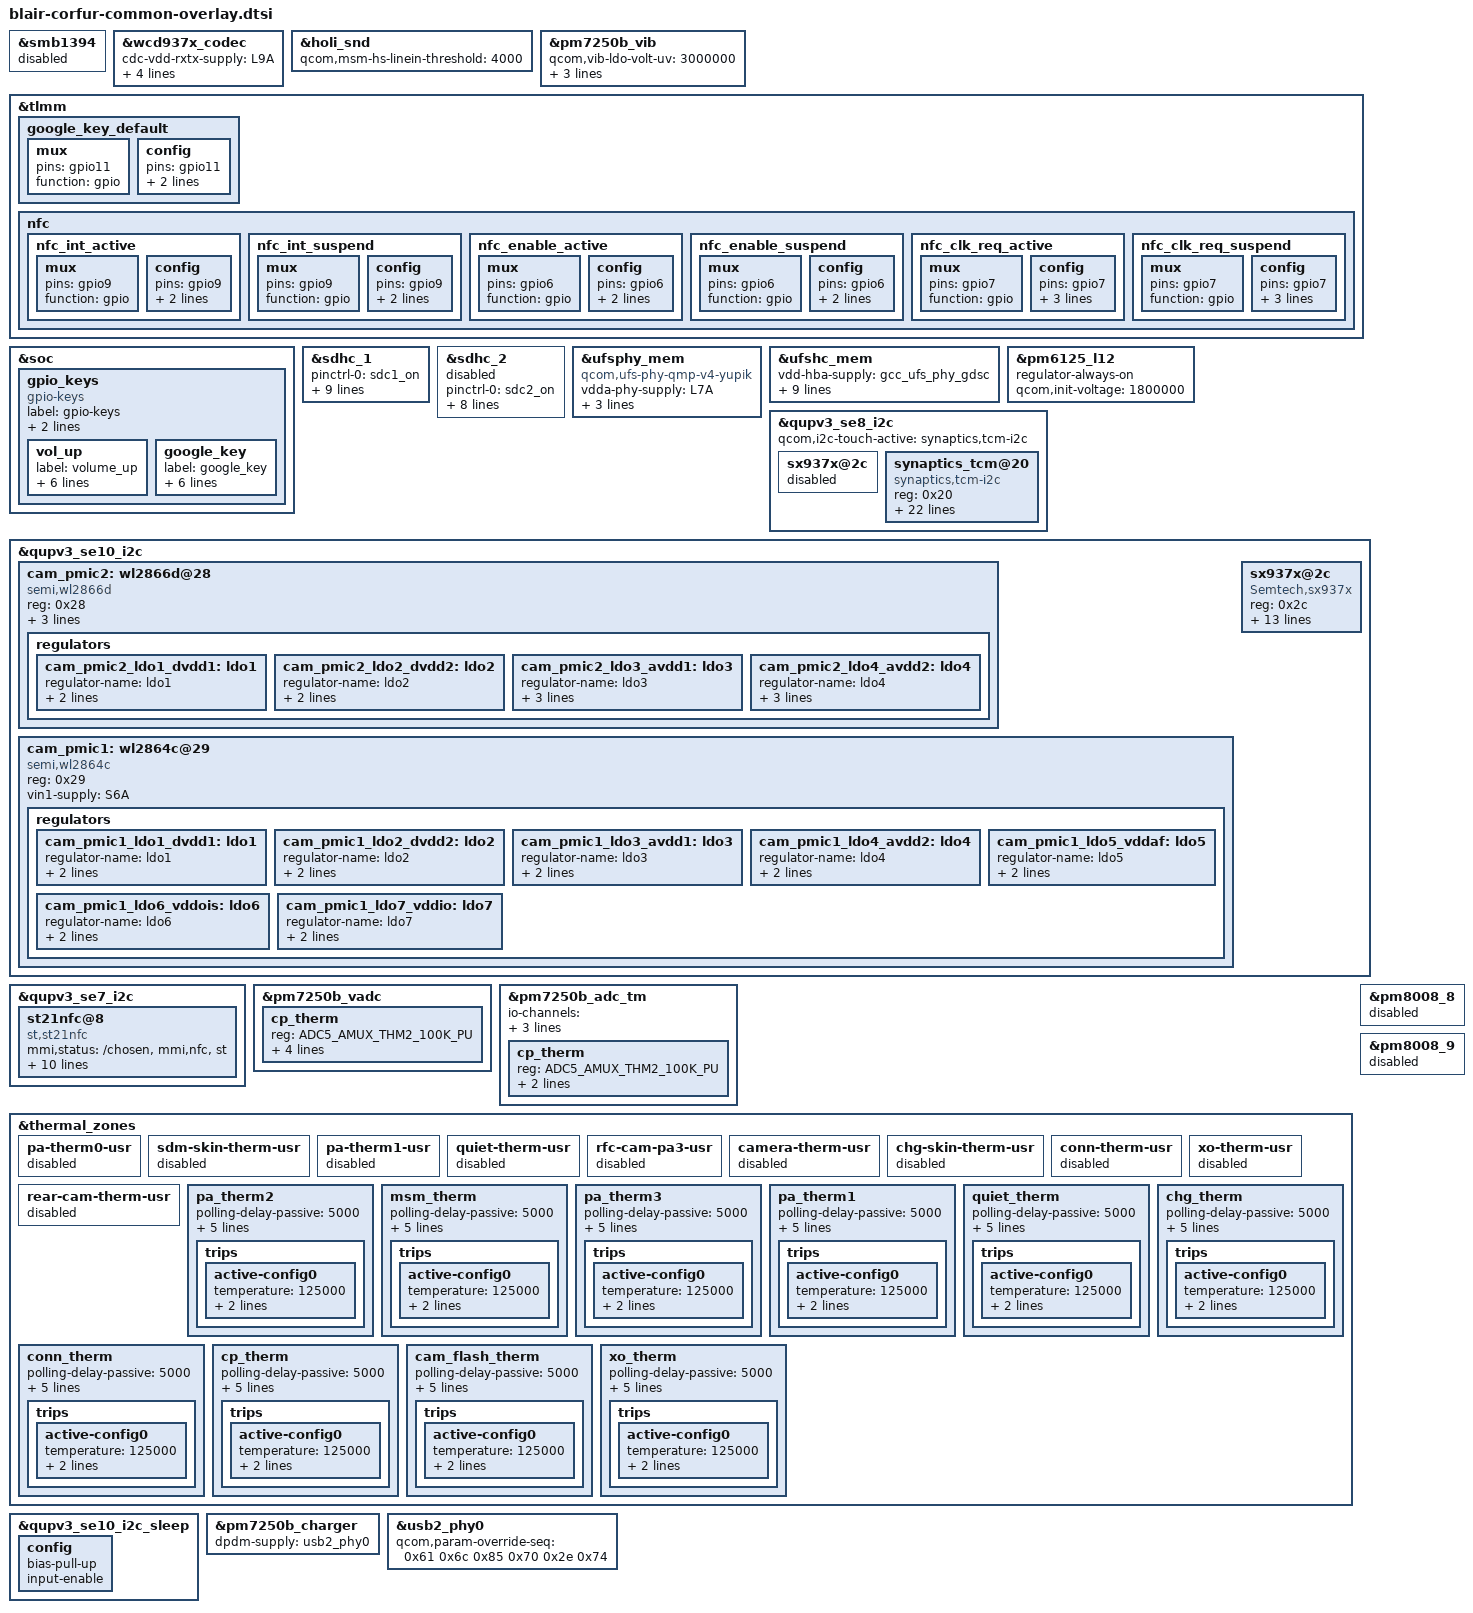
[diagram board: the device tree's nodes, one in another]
/* Copyright (c) 2021, The Linux Foundation. All rights reserved.
 *
 * This program is free software; you can redistribute it and/or modify
 * it under the terms of the GNU General Public License version 2 and
 * only version 2 as published by the Free Software Foundation.
 *
 * This program is distributed in the hope that it will be useful,
 * but WITHOUT ANY WARRANTY; without even the implied warranty of
 * MERCHANTABILITY or FITNESS FOR A PARTICULAR PURPOSE.  See the
 * GNU General Public License for more details.
 */

#include "blair-pm6125-moto-common-overlay.dtsi"
#include <dt-bindings/gpio/gpio.h>
#include <dt-bindings/input/linux-event-codes.h>
#include "holi-pmic-overlay-pm6125.dtsi"
#include "holi-thermal-overlay-pm6125.dtsi"
#include "display/holi-sde-display-mtp-pm6125.dtsi"
#include <dt-bindings/iio/qti_power_supply_iio.h>
#include "corfur-fps-overlay.dtsi"
#include "corfur-display.dtsi"
#include "corfuq-touchscreen.dtsi"
#include "holi-audio-wcd9370-aw882xx-acf-overlay.dtsi"
#include "moto_therm_sys_temp.dtsi"
#include "corfup-charger.dtsi"
#include "camera/blair-camera-sensor-mot-corfup-overlay.dtsi"
#include "camera/holi-camera-sensor-mot-corfup-dvt1-overlay.dtsi"
#include "blair-corfur-fmr-overlay.dtsi"

&smb1394 {
	status = "disabled";
};

&wcd937x_codec {
	cdc-vdd-rxtx-supply = <&L9A>;
	cdc-vddpx-supply = <&L9A>;
	qcom,cdc-static-supplies = "cdc-vdd-rxtx",
				   "cdc-vddpx";
	/*
	 * Overriding cdc-vdd-mic-bias-supply to dummy value
	 * to avoid compilation errors as BOB is not definied
	 * for pm6125
	 */
	cdc-vdd-mic-bias-supply = <>;
};

&holi_snd {
	qcom,msm-hs-linein-threshold = <4000>;
};

&pm7250b_vib {
	qcom,vib-ldo-volt-uv = <3000000>;
	qcom,vib-dis-short-long;
	qcom,vib-dis-short-long-val = <70>;
	qcom,vib-ldo-volt-uv-long = <2500000>;
};

&tlmm {
	google_key_default: google_key_default {
		mux {
			pins = "gpio11";
			function = "gpio";
		};

		config {
			pins = "gpio11";
			drive-strength = <2>;
			bias-pull-up;
		};
	};

	nfc {
		nfc_int_active: nfc_int_active {
			/* active state */
			mux {
				/* GPIO 9: NFC Read Interrupt */
				pins = "gpio9";
				function = "gpio";
			};

			config {
				pins = "gpio9";
				drive-strength = <2>; /* 2 MA */
				bias-disable;
			};
		};

		nfc_int_suspend: nfc_int_suspend {
			/* sleep state */
			mux {
				/* GPIO 9: NFC Read Interrupt */
				pins = "gpio9";
				function = "gpio";
			};

			config {
				pins = "gpio9";
				drive-strength = <2>; /* 2 MA */
				bias-disable;
			};
		};

		nfc_enable_active: nfc_enable_active {
			mux {
				/* 6: Enable */
				pins = "gpio6";
				function = "gpio";
			};

			config {
				pins = "gpio6";
				drive-strength = <2>; /* 2 MA */
				bias-disable;
			};
		};

		nfc_enable_suspend: nfc_enable_suspend {
			mux {
				/* 6: Enable */
				pins = "gpio6";
				function = "gpio";
			};

			config {
				pins = "gpio6";
				drive-strength = <2>; /* 2 MA */
				bias-disable;
			};
		};


		nfc_clk_req_active: nfc_clk_req_active {
			/* active state */
			mux {
				/* GPIO 7: NFC CLK Req*/
				pins = "gpio7";
				function = "gpio";
			};

			config {
				pins = "gpio7";
				drive-strength = <2>; /* 2 MA */
				bias-disable;
				input-enable;
			};
		};

		nfc_clk_req_suspend: nfc_clk_req_suspend {
			/* sleep state */
			mux {
				/* GPIO 7: NFC CLK Req */
				pins = "gpio7";
				function = "gpio";
			};

			config {
				pins = "gpio7";
				drive-strength = <2>; /* 2 MA */
				bias-disable;
				input-enable;
			};
		};
	};
};



&soc {
	gpio_keys: gpio_keys {
		compatible = "gpio-keys";
		label = "gpio-keys";

		pinctrl-names = "default";
		pinctrl-0 = <&key_vol_up_default &google_key_default>;

		vol_up {
			label = "volume_up";
			gpios = <&pmr735a_gpios 1 GPIO_ACTIVE_LOW>;
			linux,input-type = <1>;
			linux,code = <KEY_VOLUMEUP>;
			gpio-key,wakeup;
			debounce-interval = <15>;
			linux,can-disable;
			};

		google_key {
			label = "google_key";
			gpios = <&tlmm 11 GPIO_ACTIVE_LOW>;
			linux,input-type = <1>;
			linux,code = <KEY_SEARCH>;
			gpio-key,wakeup;
			debounce-interval = <15>;
			linux,can-disable;
			};
		};
};

/* Dummy LDO reference */
&sdhc_1 {
	status = "ok";

	pinctrl-names = "default", "sleep";
	pinctrl-0 = <&sdc1_on>;
	pinctrl-1 = <&sdc1_off>;

	vdd-supply = <&L24A>;
	qcom,vdd-voltage-level = <2960000 2960000>;
	qcom,vdd-current-level = <0 570000>;

	vdd-io-supply = <&L11A>;
	qcom,vdd-io-always-on;
	qcom,vdd-io-lpm-sup;
	qcom,vdd-io-voltage-level = <1800000 1800000>;
	qcom,vdd-io-current-level = <0 325000>;
};

&sdhc_2 {
	status = "disabled";

	pinctrl-names = "default", "sleep";
	pinctrl-0 = <&sdc2_on>;
	pinctrl-1 = <&sdc2_off>;

	vdd-supply = <&L22A>;
	qcom,vdd-voltage-level = <2960000 2960000>;
	qcom,vdd-current-level = <0 800000>;

	vdd-io-supply = <&L5A>;
	qcom,vdd-io-voltage-level = <1800000 2960000>;
	qcom,vdd-io-current-level = <0 22000>;

	cd-gpios = <&tlmm 94 GPIO_ACTIVE_LOW>;
};

&ufsphy_mem {
                compatible = "qcom,ufs-phy-qmp-v4-yupik";

                vdda-phy-supply = <&L7A>;
                vdda-pll-supply = <&L4A>;
                vdda-phy-max-microamp = <85700>;
                vdda-pll-max-microamp = <18300>;

                status = "ok";
};

&ufshc_mem {
		vdd-hba-supply = <&gcc_ufs_phy_gdsc>;
		vdd-hba-fixed-regulator;

		vcc-supply = <&L24A>;
		vcc-voltage-level = <2950000 2960000>;
		vcc-max-microamp = <800000>;

		vccq2-supply = <&L11A>;
		vccq2-max-microamp = <800000>;
		vccq2-voltage-level = <1800000 1800000>;

		qcom,vddp-ref-clk-supply = <&L4A>;
		qcom,vddp-ref-clk-max-microamp = <100>;

		status = "ok";
};


&pm6125_l12 {
	regulator-always-on;
	qcom,init-voltage = <1800000>;
};

&qupv3_se8_i2c {
	sx937x@2c {
		status = "disabled";
	};
};

&qupv3_se10_i2c {
	status = "ok";

	cam_pmic2: wl2866d@28{
		compatible = "semi,wl2866d";
		reg = <0x28>;

		vin1-supply = <&S6A>;
		semi,init-value = <0x05>;
		semi,shutdown-ldo;

		regulators {
			cam_pmic2_ldo1_dvdd1: ldo1 {
				regulator-name = "ldo1";
				regulator-min-microvolt = <600000>;
				regulator-max-microvolt = <1800000>;
			};

			cam_pmic2_ldo2_dvdd2: ldo2 {
				regulator-name = "ldo2";
				regulator-min-microvolt = <600000>;
				regulator-max-microvolt = <1800000>;
			};

			cam_pmic2_ldo3_avdd1: ldo3 {
				regulator-name = "ldo3";
				regulator-min-microvolt = <1200000>;
				regulator-max-microvolt = <4300000>;
				regulator-always-on;
			};

			cam_pmic2_ldo4_avdd2: ldo4 {
				regulator-name = "ldo4";
				regulator-min-microvolt = <3000000>;
				regulator-max-microvolt = <3000000>;
				regulator-always-on;
			};
		};
	};

	cam_pmic1: wl2864c@29{
		compatible = "semi,wl2864c";
		reg = <0x29>;

		vin1-supply = <&S6A>;

		regulators {
			cam_pmic1_ldo1_dvdd1: ldo1 {
				regulator-name = "ldo1";
				regulator-min-microvolt = <600000>;
				regulator-max-microvolt = <1800000>;
			};

			cam_pmic1_ldo2_dvdd2: ldo2 {
				regulator-name = "ldo2";
				regulator-min-microvolt = <600000>;
				regulator-max-microvolt = <1800000>;
			};

			cam_pmic1_ldo3_avdd1: ldo3 {
				regulator-name = "ldo3";
				regulator-min-microvolt = <1200000>;
				regulator-max-microvolt = <4300000>;
			};

			cam_pmic1_ldo4_avdd2: ldo4 {
				regulator-name = "ldo4";
				regulator-min-microvolt = <1200000>;
				regulator-max-microvolt = <4300000>;
			};

			cam_pmic1_ldo5_vddaf: ldo5 {
				regulator-name = "ldo5";
				regulator-min-microvolt = <1200000>;
				regulator-max-microvolt = <4300000>;
			};

			cam_pmic1_ldo6_vddois: ldo6 {
				regulator-name = "ldo6";
				regulator-min-microvolt = <1200000>;
				regulator-max-microvolt = <4300000>;
			};

			cam_pmic1_ldo7_vddio: ldo7 {
				regulator-name = "ldo7";
				regulator-min-microvolt = <1200000>;
				regulator-max-microvolt = <4300000>;
			};
		};
	};
	sx937x@2c {
		compatible = "Semtech,sx937x";
		reg = <0x2c>;
		pinctrl-names = "default","sleep";
		pinctrl-0 = <&sar_int_default>;
		pinctrl-1 = <&sar_int_sleep>;
		interrupt-parent = <&tlmm>;
		interrupts = <24 0x02>;
		interrupt-names = "sx937x_irq";
		Semtech,nirq-gpio = <&tlmm 24 0x02>;
                //please fix me
		cap_vdd-supply = <&pm6125_l12>;
		/*use PH4/5/6 as the reference sensor
		set it to 0xff if the ref-phases-x is not used*/
		Semtech,ref-phases-a = <4>;
		Semtech,ref-phases-b = <5>;
		Semtech,ref-phases-c = <6>;
		Semtech,button-flag = <0x0f>;
		Semtech,reg-num = <65>;
		Semtech,reg-init = <
			0x8024  0x7F00 		/*PHEN, Disable all Phases*/
			0x4004  0x70 		/*irq mask*/
			0x4008  0x8 		/*irq setup*/
			0x8020  0x32 		/*Set scan period*/

			/*set Phase sampling frequency to 65KHz*/
			0x8028  0x87E 		/*AFE_PARAM_PH0*/
			0x8034  0x87E 		/*AFE_PARAM_PH1*/
			0x8040  0x87E 		/*AFE_PARAM_PH2*/
			0x804C  0x87E    	/*AFE_PARAM_PH3*/
			0x8058  0x87E 		/*AFE_PARAM_PH4*/
			0x8064  0x87E 		/*AFE_PARAM_PH5*/
			0x8070  0x87E 		/*AFE_PARAM_PH6*/
			0x807C  0x876   	/*AFE_PARAM_PH7*/

			/*set CS3 to hiz, because it used as IRQ pin*/
			0x8030  0xFEF9FF 	/*REG_AFEPH_PH0, CS5, ANT1, Bottom*/
			0x803C  0xBFF9FF 	/*REG_AFEPH_PH1, CS7, ANT2, Top Right*/
			0x8048  0xFFF9FD 	/*REG_AFEPH_PH2, CS0, ANT3, Top Left*/
			0x8054  0xFFD9FF	/*REG_AFEPH_PH3, CS4, ANT4, Top Right side*/
			0x8060  0xF7F9FF 	/*REG_AFEPH_PH4, CS6, ANT1_REF, Bottom*/
			0x806C  0xFFF97F 	/*REG_AFEPH_PH5, CS2, ANT2_REF, Top Right*/
			0x8078  0xFFF9EF 	/*REG_AFEPH_PH6, CS1, ANT3_REF, WIFI GPS*/
			0x8084  0x800 	        /*REG_AFEPH_PH7, NOT USE*/

			/*Set Phase Proximity Threshold*/
			0x8098  0x693F		/*prox threshold ph0*/
			0x80B8  0x8038		/*prox threshold ph1*/
			0x80D8  0x4343		/*prox threshold ph2*/
			0x80F8  0x3C3C		/*prox threshold ph3*/
			0x8118  0x8E		/*prox threshold ph4*/
			0x8138  0x8E		/*prox threshold ph5*/
			0x8158  0x8E		/*prox threshold ph6*/
			0x8178  0x5A40	        /*prox threshold ph7*/

			/*Set Useful Filter*/
			0x80A0  0x1E1E00E1
			0x80C0  0x0
			0x80E0  0xD0D0002
			0x8100  0xF0F00E2
			0x8120  0x0
			0x8140  0x0
			0x8160  0x0
			0x8180  0x0
			0x8188  0x8000014
			0x818C  0x8000016
			0x8190  0x0
			0x8194  0x0
			0x8090  0x3CD45000
			0x80B0  0x3CD25000
			0x80D0  0x3CD45000
			0x80F0  0x3CD45000
			0x8110  0x3CD85000
			0x8130  0x3CD85000
			0x8150  0x3CD85000
			0x8170  0x3CD85000
			0x8088  0x300001
			0x80A8  0x300001
			0x80C8  0x300001
			0x80E8  0x300001
			0x8108  0x500000
			0x8128  0x500000
			0x8148  0x500000
			0x8168  0x300000
			0x808C  0x60200030
			0x80AC  0x60200030
			0x80CC  0x60200030
			0x80EC  0x60200030
			0x810C  0x60200018
			0x812C  0x60200018
			0x814C  0x60200018
			0x816C  0x60200018
			0x8024  0x7F7F 	/*PHEN, Enable PH0~PH6*/
		>;

		status = "ok";
	};
};

&qupv3_se8_i2c {
	status = "okay";
	qcom,i2c-touch-active="synaptics,tcm-i2c";

	synaptics_tcm@20 {
		compatible = "synaptics,tcm-i2c";
		reg = <0x20>;
		interrupt-parent = <&tlmm>;
		interrupts = <22 0x2008>;
		pinctrl-names = "pmx_ts_active","pmx_ts_suspend",
					"pmx_ts_release";
		pinctrl-0 = <&ts_active>;
		pinctrl-1 = <&ts_int_suspend &ts_reset_suspend>;
		pinctrl-2 = <&pmx_ts_release>;
		vdd-supply = <&L11A>;
		avdd-supply = <&L6A>;
		synaptics,pwr-reg-name = "avdd";
		synaptics,bus-reg-name = "vdd";
		synaptics,irq-gpio = <&tlmm 22 0x2008>;
		synaptics,irq-on-state = <0>;
		synaptics,reset-gpio = <&tlmm 21 0x00>;
		synaptics,reset-on-state = <0>;
		synaptics,reset-active-ms = <20>;
		synaptics,reset-delay-ms = <200>;
		synaptics,power-delay-ms = <200>;
		synaptics,ubl-i2c-addr = <0x20>;
		synaptics,extend_report;
		synaptics,firmware-name = "synaptics_firmware.img";

		panel = <&dsi_rm69299_visionox_amoled_video
			&dsi_rm69299_visionox_amoled_cmd>;
	};
};

&qupv3_se7_i2c {
	status = "ok";
	#address-cells = <1>;
	#size-cells = <0>;
	st21nfc@8 {
		compatible = "st,st21nfc";
		mmi,status = "/chosen", "mmi,nfc", "st";
		status = "ok";
		reg = <0x08>;
		st,irq_gpio = <&tlmm 9 0x00>;
		st,reset_gpio = <&tlmm 6 0x00>;
		st,clkreq_gpio = <&tlmm 7 0x00>;
		interrupt-parent = <&tlmm>;
		interrupts = <9 0>;
		interrupt-names = "nfc_irq";
		pinctrl-names = "nfc_active", "nfc_suspend";
		pinctrl-0 = <&nfc_int_active &nfc_enable_active
				&nfc_clk_req_active>;
		pinctrl-1 = <&nfc_int_suspend &nfc_enable_suspend
				&nfc_clk_req_suspend>;
	};
};

&pm7250b_vadc {
	cp_therm {
		reg = <ADC5_AMUX_THM2_100K_PU>;
		label = "cp_therm";
		qcom,ratiometric;
		qcom,hw-settle-time = <200>;
		qcom,pre-scaling = <1 1>;
	};
};

&pm7250b_adc_tm {
	io-channels = <&pm7250b_vadc ADC5_AMUX_THM1_100K_PU>,
			<&pm7250b_vadc ADC5_AMUX_THM2_100K_PU>,
			<&pm7250b_vadc ADC5_AMUX_THM3_100K_PU>;

	cp_therm {
		reg = <ADC5_AMUX_THM2_100K_PU>;
		qcom,ratiometric;
		qcom,hw-settle-time = <200>;
	};
};

&thermal_zones {
	pa-therm0-usr {
		status = "disabled";
	};
	sdm-skin-therm-usr {
		status = "disabled";
	};
	pa-therm1-usr {
		status = "disabled";
	};
	quiet-therm-usr {
		status = "disabled";
	};
	rfc-cam-pa3-usr {
		status = "disabled";
	};
	camera-therm-usr {
		status = "disabled";
	};
	chg-skin-therm-usr {
		status = "disabled";
	};
	conn-therm-usr {
		status = "disabled";
	};
	xo-therm-usr {
		status = "disabled";
	};
	rear-cam-therm-usr {
		status = "disabled";
	};

	pa_therm2 {
		polling-delay-passive = <5000>;
		polling-delay = <20000>;
		thermal-governor = "user_space";
		thermal-sensors = <&pm6125_adc_tm ADC5_GPIO4_100K_PU>;
		wake-capable-sensor;
		trips {
			active-config0 {
				temperature = <125000>;
				hysteresis = <1000>;
				type = "passive";
			};
		};
	};
	msm_therm {
		polling-delay-passive = <5000>;
		polling-delay = <20000>;
		thermal-governor = "user_space";
		thermal-sensors = <&pm6125_adc_tm_iio ADC5_GPIO1_100K_PU>;
		wake-capable-sensor;
		trips {
			active-config0 {
				temperature = <125000>;
				hysteresis = <1000>;
				type = "passive";
			};
		};
	};
	pa_therm3 {
		polling-delay-passive = <5000>;
		polling-delay = <20000>;
		thermal-governor = "user_space";
		thermal-sensors = <&pm6125_adc_tm_iio ADC5_GPIO2_100K_PU>;
		wake-capable-sensor;
		trips {
			active-config0 {
				temperature = <125000>;
				hysteresis = <1000>;
				type = "passive";
			};
		};
	};
	pa_therm1 {
		polling-delay-passive = <5000>;
		polling-delay = <20000>;
		thermal-governor = "user_space";
		thermal-sensors = <&pm6125_adc_tm ADC5_AMUX_THM1_100K_PU>;
		wake-capable-sensor;
		trips {
			active-config0 {
				temperature = <125000>;
				hysteresis = <1000>;
				type = "passive";
			};
		};
	};
	quiet_therm {
		polling-delay-passive = <5000>;
		polling-delay = <20000>;
		thermal-governor = "user_space";
		thermal-sensors = <&pm6125_adc_tm ADC5_AMUX_THM2_100K_PU>;
		wake-capable-sensor;
		trips {
			active-config0 {
				temperature = <125000>;
				hysteresis = <1000>;
				type = "passive";
			};
		};
	};
	chg_therm {
		polling-delay-passive = <5000>;
		polling-delay = <20000>;
		thermal-governor = "user_space";
		thermal-sensors = <&pm7250b_adc_tm ADC5_AMUX_THM1_100K_PU>;
		wake-capable-sensor;
		trips {
			active-config0 {
				temperature = <125000>;
				hysteresis = <1000>;
				type = "passive";
			};
		};
	};
	conn_therm {
		polling-delay-passive = <5000>;
		polling-delay = <20000>;
		thermal-governor = "user_space";
		thermal-sensors = <&pm7250b_adc_tm ADC5_AMUX_THM3_100K_PU>;
		wake-capable-sensor;
		trips {
			active-config0 {
				temperature = <125000>;
				hysteresis = <1000>;
				type = "passive";
			};
		};
	};
	cp_therm {
		polling-delay-passive = <5000>;
		polling-delay = <20000>;
		thermal-governor = "user_space";
		thermal-sensors = <&pm7250b_adc_tm ADC5_AMUX_THM2_100K_PU>;
		wake-capable-sensor;
		trips {
			active-config0 {
				temperature = <125000>;
				hysteresis = <1000>;
				type = "passive";
			};
		};
	};
	cam_flash_therm {
		polling-delay-passive = <5000>;
		polling-delay = <20000>;
		thermal-governor = "user_space";
		thermal-sensors = <&pm6125_adc_tm ADC5_GPIO3_100K_PU>;
		wake-capable-sensor;
		trips {
			active-config0 {
				temperature = <125000>;
				hysteresis = <1000>;
				type = "passive";
			};
		};
	};
	xo_therm {
		polling-delay-passive = <5000>;
		polling-delay = <20000>;
		thermal-governor = "user_space";
		thermal-sensors = <&pmk8350_adc_tm PMK8350_ADC7_AMUX_THM1_100K_PU>;
		wake-capable-sensor;
		trips {
			active-config0 {
				temperature = <125000>;
				hysteresis = <1000>;
				type = "passive";
			};
		};
	};
};

&pm8008_8 {
	status = "disabled";
};

&pm8008_9 {
	status = "disabled";
};

&sdhc_2 {
	qcom,vdd-voltage-level = <3000000 3000000>;
};

&qupv3_se10_i2c_sleep {
	config {
		/delete-property/ bias-disable;
		bias-pull-up;
		input-enable;
	};
};


&pm7250b_charger {
	dpdm-supply = <&usb2_phy0>;
};

&usb2_phy0 {
	qcom,param-override-seq =
		<0x61 0x6c	/* override_x0 */
		0x85 0x70	/* override_x1 */
		0x2e 0x74>;	/* override x2 */
};
